# FM33LE0XXA register map
File version: 1.0
CPU: SC000 r1p0, little endian, no MPU, no FPU, 3 interrupt priority bits
Registers are 32-bit, read-write, reset 0x0 unless marked. A register's access mark holds for its fields unless they carry their own. Offsets are from the block's base; [hi:lo] are bit positions.

## SPI1 — SPI1 module information
Base 0x40018C00
Same registers: SPI2 0x40010800
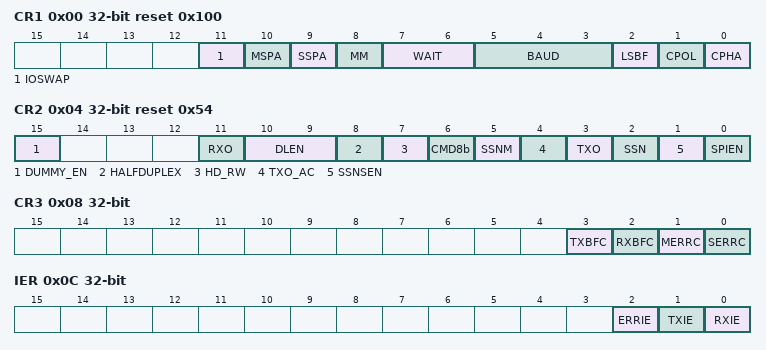
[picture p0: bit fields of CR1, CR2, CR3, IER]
0x00 CR1 reset 0x100 — SPI1 Control Register1
  [11] IOSWAP — IOSWAP field description
  [10] MSPA — MSPA field description
  [9] SSPA — SSPA field description
  [8] MM — MM field description
  [7:6] WAIT — WAIT field description
  [5:3] BAUD — BAUD field description
  [2] LSBF — LSBF field description
  [1] CPOL — CPOL field description
  [0] CPHA — CPHA field description
0x04 CR2 reset 0x54 — SPI1 Control Register2
  [15] DUMMY_EN — DUMMY_EN field description
  [11] RXO — RXO field description
  [10:9] DLEN — DLEN field description
  [8] HALFDUPLEX — HALFDUPLEX field description
  [7] HD_RW — HD_RW field description
  [6] CMD8b — CMD8b field description
  [5] SSNM — SSNM field description
  [4] TXO_AC — TXO_AC field description
  [3] TXO — TXO field description
  [2] SSN — SSN field description
  [1] SSNSEN — SSNSEN field description
  [0] SPIEN — SPIEN field description
0x08 CR3 wo — SPI1 Control Register3
  [3] TXBFC — TXBFC field description
  [2] RXBFC — RXBFC field description
  [1] MERRC — MERRC field description
  [0] SERRC — SERRC field description
0x0C IER — SPI1 Interrupt Enable Register
  [2] ERRIE — ERRIE field description
  [1] TXIE — TXIE field description
  [0] RXIE — RXIE field description
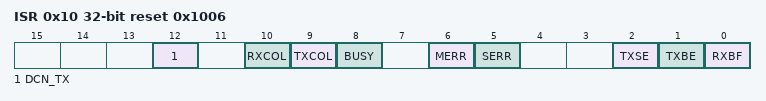
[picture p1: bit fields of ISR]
0x10 ISR access per field reset 0x1006 — SPI1 Status Register
  [12] DCN_TX rw — DCN_TX field description
  [10] RXCOL rw — RXCOL field description
  [9] TXCOL rw — TXCOL field description
  [8] BUSY ro — BUSY field description
  [6] MERR ro — MERR field description
  [5] SERR ro — SERR field description
  [2] TXSE ro — TXSE field description
  [1] TXBE ro — TXBE field description
  [0] RXBF ro — RXBF field description
0x14 TXBUF wo — SPI1 Transmit Buffer
  [31:0] TXBUF — TXBUF field description
0x18 RXBUF ro — SPI1 Receive Buffer
  [31:0] RXBUF — RXBUF field description

## U7816 — U7816 module information
Base 0x40010000
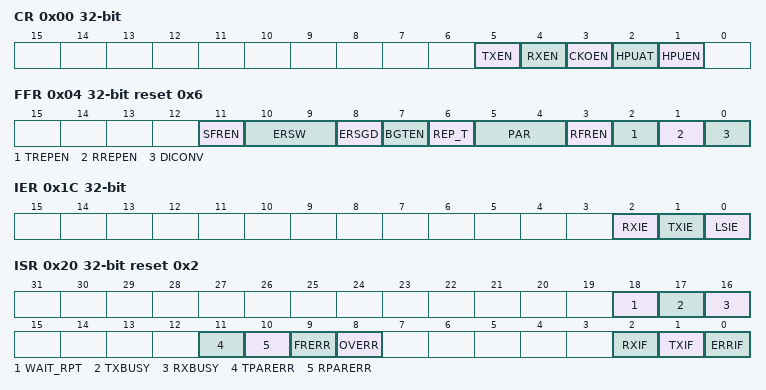
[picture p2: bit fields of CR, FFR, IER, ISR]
0x00 CR — U7816 Control Register
  [5] TXEN — TXEN field description
  [4] RXEN — RXEN field description
  [3] CKOEN — CKOEN field description
  [2] HPUAT — HPUAT field description
  [1] HPUEN — HPUEN field description
0x04 FFR reset 0x6 — U7816 Frame Format Register
  [11] SFREN — SFREN field description
  [10:9] ERSW — ERSW field description
  [8] ERSGD — ERSGD field description
  [7] BGTEN — BGTEN field description
  [6] REP_T — REP_T field description
  [5:4] PAR — PAR field description
  [3] RFREN — RFREN field description
  [2] TREPEN — TREPEN field description
  [1] RREPEN — RREPEN field description
  [0] DICONV — DICONV field description
0x08 EGTR — U7816 Extra Guard Time Register
  [7:0] TXEGT — TXEGT field description
0x0C PSC — U7816 Prescaler Register
  [4:0] CLKDIV — CLKDIV field description
0x10 BGR reset 0x100 — U7816 Baud rate Generator Register
  [11:0] PDIV — PDIV field description
0x14 RXBUF ro — U7816 Receive Buffer
  [7:0] RXBUF — RXBUF field description
0x18 TXBUF wo — U7816 Transmit Buffer
  [7:0] TXBUF — TXBUF field description
0x1C IER — U7816 Interrupt Enable Register
  [2] RXIE — RXIE field description
  [1] TXIE — TXIE field description
  [0] LSIE — LSIE field description
0x20 ISR access per field reset 0x2 — U7816 Interrupt Status Register
  [18] WAIT_RPT ro — WAIT_RPT field description
  [17] TXBUSY ro — TXBUSY field description
  [16] RXBUSY ro — RXBUSY field description
  [11] TPARERR rw — TPARERR field description
  [10] RPARERR rw — RPARERR field description
  [9] FRERR rw — FRERR field description
  [8] OVERR rw — OVERR field description
  [2] RXIF ro — RXIF field description
  [1] TXIF ro — TXIF field description
  [0] ERRIF ro — ERRIF field description
